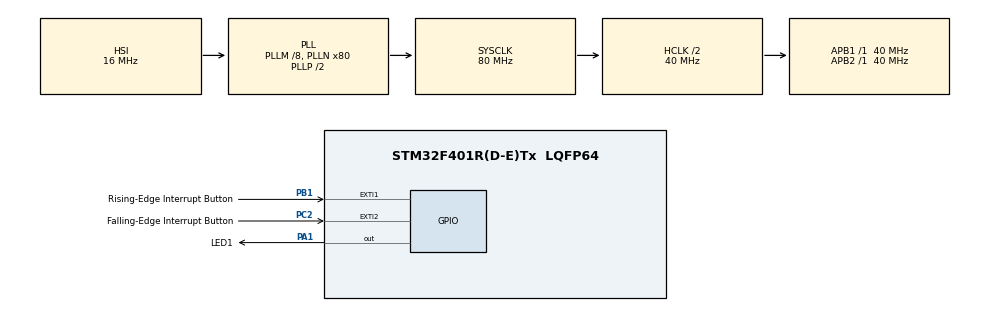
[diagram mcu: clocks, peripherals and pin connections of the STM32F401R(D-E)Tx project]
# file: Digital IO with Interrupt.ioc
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Mcu.Family=STM32F4
Mcu.Name=STM32F401R(D-E)Tx
Mcu.Package=LQFP64
NVIC.EXTI1_IRQn=true\:1\:0\:true\:false\:true\:true\:true
NVIC.EXTI2_IRQn=true\:1\:0\:true\:false\:true\:true\:true
NVIC.PriorityGroup=NVIC_PRIORITYGROUP_4
PA1.GPIO_Label=LED1
PA1.Signal=GPIO_Output
PB1.GPIO_Label=Rising-Edge Interrupt Button
PB1.Signal=GPXTI1
PC2.GPIO_Label=Falling-Edge Interrupt Button
PC2.GPIO_ModeDefaultEXTI=GPIO_MODE_IT_FALLING
PC2.Signal=GPXTI2
PH0\ -\ OSC_IN.Mode=HSE-External-Oscillator
PH0\ -\ OSC_IN.Signal=RCC_OSC_IN
PH1\ -\ OSC_OUT.Mode=HSE-External-Oscillator
PH1\ -\ OSC_OUT.Signal=RCC_OSC_OUT
ProjectManager.HeapSize=0x200
ProjectManager.StackSize=0x400
ProjectManager.TargetToolchain=STM32CubeIDE
RCC.48MHZClocksFreq_Value=40000000
RCC.AHBCLKDivider=RCC_SYSCLK_DIV2
RCC.AHBFreq_Value=40000000
RCC.APB1Freq_Value=40000000
RCC.APB1TimFreq_Value=40000000
RCC.APB2Freq_Value=40000000
RCC.APB2TimFreq_Value=40000000
RCC.CortexFreq_Value=40000000
RCC.HCLKFreq_Value=40000000
RCC.HSE_VALUE=25000000
RCC.HSI_VALUE=16000000
RCC.LSE_VALUE=32768
RCC.PLLM=8
RCC.PLLN=80
RCC.SYSCLKFreq_VALUE=80000000
RCC.SYSCLKSource=RCC_SYSCLKSOURCE_PLLCLK
RCC.VCOOutputFreq_Value=160000000
board=custom

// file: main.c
/* USER CODE BEGIN Header */
/**
  ******************************************************************************
  * @file           : main.c
  * @brief          : Main program body
  ******************************************************************************
  * @attention
  *
  * <h2><center>&copy; Copyright (c) 2020 STMicroelectronics.
  * All rights reserved.</center></h2>
  *
  * This software component is licensed by ST under BSD 3-Clause license,
  * the "License"; You may not use this file except in compliance with the
  * License. You may obtain a copy of the License at:
  *                        opensource.org/licenses/BSD-3-Clause
  *
  ******************************************************************************
  */
/* USER CODE END Header */

#include "main.h"

/* USER CODE BEGIN PV */
uint16_t InterruptCounter,LoopInfiniteCounter;

/* USER CODE END PV */

void SystemClock_Config(void);
static void MX_GPIO_Init(void);

int main(void)
{

  /* MCU Configuration--------------------------------------------------------*/

  /* Reset of all peripherals, Initializes the Flash interface and the Systick. */
  HAL_Init();

  /* Configure the system clock */
  SystemClock_Config();

  /* Initialize all configured peripherals */
  MX_GPIO_Init();

  /* Infinite loop */
  while (1)
  {

  }
}

void SystemClock_Config(void)
{
  RCC_OscInitTypeDef RCC_OscInitStruct = {0};
  RCC_ClkInitTypeDef RCC_ClkInitStruct = {0};

  /** Configure the main internal regulator output voltage
  */
  __HAL_RCC_PWR_CLK_ENABLE();
  __HAL_PWR_VOLTAGESCALING_CONFIG(PWR_REGULATOR_VOLTAGE_SCALE2);
  /** Initializes the CPU, AHB and APB busses clocks
  */
  RCC_OscInitStruct.OscillatorType = RCC_OSCILLATORTYPE_HSI;
  RCC_OscInitStruct.HSIState = RCC_HSI_ON;
  RCC_OscInitStruct.HSICalibrationValue = RCC_HSICALIBRATION_DEFAULT;
  RCC_OscInitStruct.PLL.PLLState = RCC_PLL_ON;
  RCC_OscInitStruct.PLL.PLLSource = RCC_PLLSOURCE_HSI;
  RCC_OscInitStruct.PLL.PLLM = 8;
  RCC_OscInitStruct.PLL.PLLN = 80;
  RCC_OscInitStruct.PLL.PLLP = RCC_PLLP_DIV2;
  RCC_OscInitStruct.PLL.PLLQ = 4;
  if (HAL_RCC_OscConfig(&RCC_OscInitStruct) != HAL_OK)
  {
    Error_Handler();
  }
  /** Initializes the CPU, AHB and APB busses clocks
  */
  RCC_ClkInitStruct.ClockType = RCC_CLOCKTYPE_HCLK|RCC_CLOCKTYPE_SYSCLK
                              |RCC_CLOCKTYPE_PCLK1|RCC_CLOCKTYPE_PCLK2;
  RCC_ClkInitStruct.SYSCLKSource = RCC_SYSCLKSOURCE_PLLCLK;
  RCC_ClkInitStruct.AHBCLKDivider = RCC_SYSCLK_DIV2;
  RCC_ClkInitStruct.APB1CLKDivider = RCC_HCLK_DIV1;
  RCC_ClkInitStruct.APB2CLKDivider = RCC_HCLK_DIV1;

  if (HAL_RCC_ClockConfig(&RCC_ClkInitStruct, FLASH_LATENCY_1) != HAL_OK)
  {
    Error_Handler();
  }
}

static void MX_GPIO_Init(void)
{
  GPIO_InitTypeDef GPIO_InitStruct = {0};

  /* GPIO Ports Clock Enable */
  __HAL_RCC_GPIOH_CLK_ENABLE();
  __HAL_RCC_GPIOC_CLK_ENABLE();
  __HAL_RCC_GPIOA_CLK_ENABLE();
  __HAL_RCC_GPIOB_CLK_ENABLE();

  /*Configure GPIO pin Output Level */
  HAL_GPIO_WritePin(LED1_GPIO_Port, LED1_Pin, GPIO_PIN_RESET);

  /*Configure GPIO pin : Falling_Edge_Interrupt_Button_Pin */
  GPIO_InitStruct.Pin = Falling_Edge_Interrupt_Button_Pin;
  GPIO_InitStruct.Mode = GPIO_MODE_IT_FALLING;
  GPIO_InitStruct.Pull = GPIO_NOPULL;
  HAL_GPIO_Init(Falling_Edge_Interrupt_Button_GPIO_Port, &GPIO_InitStruct);

  /*Configure GPIO pin : LED1_Pin */
  GPIO_InitStruct.Pin = LED1_Pin;
  GPIO_InitStruct.Mode = GPIO_MODE_OUTPUT_PP;
  GPIO_InitStruct.Pull = GPIO_NOPULL;
  GPIO_InitStruct.Speed = GPIO_SPEED_FREQ_LOW;
  HAL_GPIO_Init(LED1_GPIO_Port, &GPIO_InitStruct);

  /*Configure GPIO pin : Rising_Edge_Interrupt_Button_Pin */
  GPIO_InitStruct.Pin = Rising_Edge_Interrupt_Button_Pin;
  GPIO_InitStruct.Mode = GPIO_MODE_IT_RISING;
  GPIO_InitStruct.Pull = GPIO_NOPULL;
  HAL_GPIO_Init(Rising_Edge_Interrupt_Button_GPIO_Port, &GPIO_InitStruct);

  /* EXTI interrupt init*/
  HAL_NVIC_SetPriority(EXTI1_IRQn, 1, 0);
  HAL_NVIC_EnableIRQ(EXTI1_IRQn);

  HAL_NVIC_SetPriority(EXTI2_IRQn, 1, 0);
  HAL_NVIC_EnableIRQ(EXTI2_IRQn);

}

void Error_Handler(void)
{
}

/************************ (C) COPYRIGHT STMicroelectronics *****END OF FILE****/
